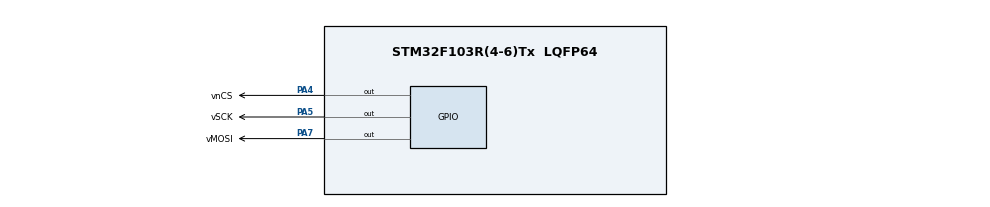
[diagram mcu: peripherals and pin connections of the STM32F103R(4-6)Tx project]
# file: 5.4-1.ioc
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Mcu.Family=STM32F1
Mcu.Name=STM32F103R(4-6)Tx
Mcu.Package=LQFP64
NVIC.PriorityGroup=NVIC_PRIORITYGROUP_4
PA4.GPIO_Label=vnCS
PA4.GPIO_ModeDefaultOutputPP=GPIO_MODE_OUTPUT_OD
PA4.GPIO_PuPd=GPIO_PULLUP
PA4.PinState=GPIO_PIN_SET
PA4.Signal=GPIO_Output
PA5.GPIO_Label=vSCK
PA5.GPIO_ModeDefaultOutputPP=GPIO_MODE_OUTPUT_OD
PA5.GPIO_PuPd=GPIO_PULLUP
PA5.GPIO_Speed=GPIO_SPEED_FREQ_HIGH
PA5.PinState=GPIO_PIN_SET
PA5.Signal=GPIO_Output
PA7.GPIO_Label=vMOSI
PA7.GPIO_ModeDefaultOutputPP=GPIO_MODE_OUTPUT_OD
PA7.GPIO_PuPd=GPIO_PULLUP
PA7.GPIO_Speed=GPIO_SPEED_FREQ_HIGH
PA7.PinState=GPIO_PIN_SET
PA7.Signal=GPIO_Output
ProjectManager.HeapSize=0x200
ProjectManager.StackSize=0x400
ProjectManager.TargetToolchain=STM32CubeIDE
RCC.APB1Freq_Value=8000000
RCC.APB2Freq_Value=8000000
VP_SYS_VS_ND.Mode=No_Debug
board=custom

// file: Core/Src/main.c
/* USER CODE BEGIN Header */
/**
  ******************************************************************************
  * @file           : main.c
  * @brief          : Main program body
  ******************************************************************************
  * @attention
  *
  * <h2><center>&copy; Copyright (c) 2020 STMicroelectronics.
  * All rights reserved.</center></h2>
  *
  * This software component is licensed by ST under BSD 3-Clause license,
  * the "License"; You may not use this file except in compliance with the
  * License. You may obtain a copy of the License at:
  *                        opensource.org/licenses/BSD-3-Clause
  *
  ******************************************************************************
  */
/* USER CODE END Header */
#include "main.h"

/* USER CODE BEGIN Includes */
#include "vSPI.h"
#include "MCP4921.h"
/* USER CODE END Includes */

/* USER CODE BEGIN PV */
static uint16_t tD[50]=
{512,576,639,700,759,813,862,907,944,975,999,1015,1023,1023,1015,
999,975,944,907,862,813,759,700,639,576,512,448,385,324,265,
211,162,117,80,49,25,9,1,1,9,25,49,80,117,162,211,265,324,385,448};
/* USER CODE END PV */

void SystemClock_Config(void);
static void MX_GPIO_Init(void);

int main(void)
{
  /* USER CODE BEGIN 1 */
	int i;
  /* USER CODE END 1 */

  /* MCU Configuration--------------------------------------------------------*/

  /* Reset of all peripherals, Initializes the Flash interface and the Systick. */
  HAL_Init();

  /* Configure the system clock */
  SystemClock_Config();

  /* Initialize all configured peripherals */
  MX_GPIO_Init();

  /* Infinite loop */
  /* USER CODE BEGIN WHILE */
  while (1)
  {
	  for(i=0;i<50;i++)
	  {
		  MCP4921Write(0x70,tD[i]);
		  HAL_Delay(20);
	  }
    /* USER CODE END WHILE */

  }
}

void SystemClock_Config(void)
{
  RCC_OscInitTypeDef RCC_OscInitStruct = {0};
  RCC_ClkInitTypeDef RCC_ClkInitStruct = {0};

  /** Initializes the RCC Oscillators according to the specified parameters
  * in the RCC_OscInitTypeDef structure.
  */
  RCC_OscInitStruct.OscillatorType = RCC_OSCILLATORTYPE_HSI;
  RCC_OscInitStruct.HSIState = RCC_HSI_ON;
  RCC_OscInitStruct.HSICalibrationValue = RCC_HSICALIBRATION_DEFAULT;
  RCC_OscInitStruct.PLL.PLLState = RCC_PLL_NONE;
  if (HAL_RCC_OscConfig(&RCC_OscInitStruct) != HAL_OK)
  {
    Error_Handler();
  }
  /** Initializes the CPU, AHB and APB buses clocks
  */
  RCC_ClkInitStruct.ClockType = RCC_CLOCKTYPE_HCLK|RCC_CLOCKTYPE_SYSCLK
                              |RCC_CLOCKTYPE_PCLK1|RCC_CLOCKTYPE_PCLK2;
  RCC_ClkInitStruct.SYSCLKSource = RCC_SYSCLKSOURCE_HSI;
  RCC_ClkInitStruct.AHBCLKDivider = RCC_SYSCLK_DIV1;
  RCC_ClkInitStruct.APB1CLKDivider = RCC_HCLK_DIV1;
  RCC_ClkInitStruct.APB2CLKDivider = RCC_HCLK_DIV1;

  if (HAL_RCC_ClockConfig(&RCC_ClkInitStruct, FLASH_LATENCY_0) != HAL_OK)
  {
    Error_Handler();
  }
}

static void MX_GPIO_Init(void)
{
  GPIO_InitTypeDef GPIO_InitStruct = {0};

  /* GPIO Ports Clock Enable */
  __HAL_RCC_GPIOA_CLK_ENABLE();

  /*Configure GPIO pin Output Level */
  HAL_GPIO_WritePin(GPIOA, vnCS_Pin|vSCK_Pin|vMOSI_Pin, GPIO_PIN_SET);

  /*Configure GPIO pin : vnCS_Pin */
  GPIO_InitStruct.Pin = vnCS_Pin;
  GPIO_InitStruct.Mode = GPIO_MODE_OUTPUT_OD;
  GPIO_InitStruct.Pull = GPIO_PULLUP;
  GPIO_InitStruct.Speed = GPIO_SPEED_FREQ_LOW;
  HAL_GPIO_Init(vnCS_GPIO_Port, &GPIO_InitStruct);

  /*Configure GPIO pins : vSCK_Pin vMOSI_Pin */
  GPIO_InitStruct.Pin = vSCK_Pin|vMOSI_Pin;
  GPIO_InitStruct.Mode = GPIO_MODE_OUTPUT_OD;
  GPIO_InitStruct.Pull = GPIO_PULLUP;
  GPIO_InitStruct.Speed = GPIO_SPEED_FREQ_HIGH;
  HAL_GPIO_Init(GPIOA, &GPIO_InitStruct);

}

void Error_Handler(void)
{
}

/************************ (C) COPYRIGHT STMicroelectronics *****END OF FILE****/
